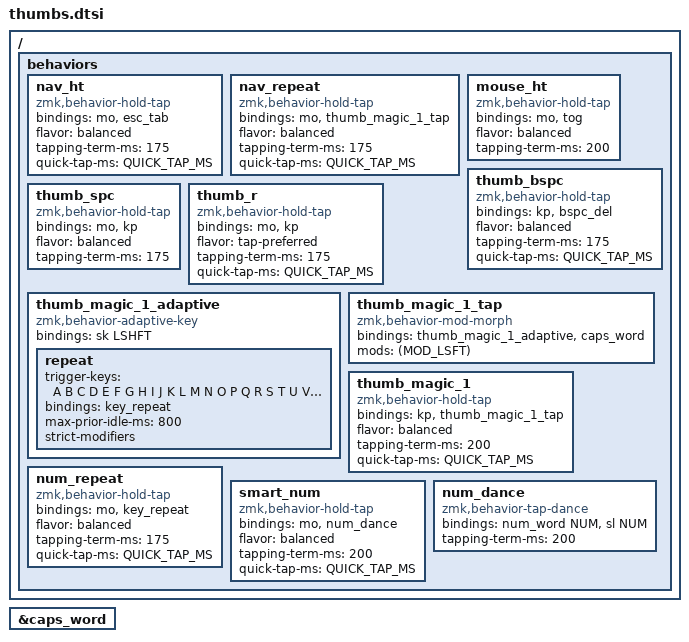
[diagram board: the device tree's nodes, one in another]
ZMK_HOLD_TAP(nav_ht, bindings = <&mo>, <&esc_tab>;
             flavor = "balanced"; tapping-term-ms = <175>;
             quick-tap-ms = <QUICK_TAP_MS>;)

ZMK_HOLD_TAP(nav_repeat, bindings = <&mo>, <&thumb_magic_1_tap>;
             flavor = "balanced"; tapping-term-ms = <175>;
             quick-tap-ms = <QUICK_TAP_MS>;)

ZMK_HOLD_TAP(mouse_ht, bindings = <&mo>, <&tog>;
             flavor = "balanced"; tapping-term-ms = <200>;)

ZMK_HOLD_TAP(thumb_bspc, bindings = <&kp>, <&bspc_del>;
             flavor = "balanced"; tapping-term-ms = <175>;
             quick-tap-ms = <QUICK_TAP_MS>;)

ZMK_HOLD_TAP(thumb_spc, bindings = <&mo>, <&kp>;
             flavor = "balanced"; tapping-term-ms = <175>;)

ZMK_HOLD_TAP(thumb_r, bindings = <&mo>, <&kp>;
             flavor = "tap-preferred"; tapping-term-ms = <175>;
             quick-tap-ms = <QUICK_TAP_MS>;)

/* ── Thumb magic (adaptive repeat/shift) ─────────────────────────────── */

#define AK(name, k, b) \
    name { trigger-keys = <k>; max-prior-idle-ms = <800>; bindings = <b>; };

ZMK_ADAPTIVE_KEY(thumb_magic_1_adaptive, bindings = <&sk LSHFT>;
    repeat {
      trigger-keys = <A B C D E F G H I J K L M N O P Q R S T U V W X Y Z>;
      bindings = <&key_repeat>;
      max-prior-idle-ms = <800>;
      strict-modifiers;
    };
)

ZMK_MOD_MORPH(thumb_magic_1_tap, bindings = <&thumb_magic_1_adaptive>, <&caps_word>;
              mods = <(MOD_LSFT)>;)

ZMK_HOLD_TAP(thumb_magic_1, bindings = <&kp>, <&thumb_magic_1_tap>;
             flavor = "balanced"; tapping-term-ms = <200>;
             quick-tap-ms = <QUICK_TAP_MS>;)

ZMK_HOLD_TAP(num_repeat, bindings = <&mo>, <&key_repeat>;
             flavor = "balanced"; tapping-term-ms = <175>;
             quick-tap-ms = <QUICK_TAP_MS>;)
&caps_word { // Mods deactivate caps-word, requires PR #1451. [TODO: rebase]
  /delete-property/ ignore-modifiers;
};

#define THUMB_MAGIC &thumb_magic_1 LSHFT 0

/* ── Auto Layers ─────────────────────────────────────────────────────── */

// Tap: num-word | double-tap: sticky num-layer | Hold: num-layer.
#define SMART_NUM &smart_num NUM 0
ZMK_HOLD_TAP(smart_num, bindings = <&mo>, <&num_dance>; flavor = "balanced";
             tapping-term-ms = <200>; quick-tap-ms = <QUICK_TAP_MS>;)
ZMK_TAP_DANCE(num_dance, bindings = <&num_word NUM>, <&sl NUM>;
              tapping-term-ms = <200>;)

// Smart-mouse, requires tri-state module.
ZMK_TRI_STATE(
    smart_mouse, bindings = <&tog MOUSE>, <&none>, <&tog MOUSE>;
    ignored-key-positions =
        <LT1 LT2 LH0 LH1 RT1 RT2 RT3 RM0 RM1 RM2 RM3 RM4 RB1 RB2 RB3 RH0 RH1>;
    ignored-layers = <MOUSE NAV FN>;)
